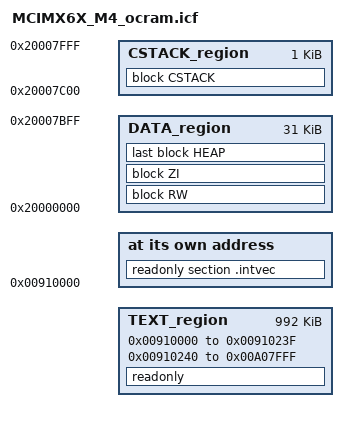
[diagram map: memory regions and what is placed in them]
/*
** ###################################################################
**     Processors:          MCIMX6Xxxxx08AB
**                          MCIMX6Xxxxx10AB
**
**     Compiler:            IAR ANSI C/C++ Compiler for ARM
**     Reference manual:    IMX6SXRM, Rev.A, February 2015
**     Version:             rev. 1.0, 2015-07-29
**
**     Abstract:
**         Linker file for the IAR ANSI C/C++ Compiler for ARM
**
**     Copyright (c) 2015 Freescale Semiconductor, Inc.
**     Copyright 2016 NXP
**     All rights reserved.
**
**     
**     SPDX-License-Identifier: BSD-3-Clause
**
**     http:                 www.freescale.com
**     mail:                 support@freescale.com
**
** ###################################################################
*/

define symbol m_interrupts_start       = 0x00910000;
define symbol m_interrupts_end         = 0x0091023F;

define symbol m_text_start             = 0x00910240;
define symbol m_text_end               = 0x00A07FFF;

define symbol m_data_start             = 0x20000000;
define symbol m_data_end               = 0x20007FFF;


/* Sizes */
if (isdefinedsymbol(__stack_size__)) {
  define symbol __size_cstack__        = __stack_size__;
} else {
  define symbol __size_cstack__        = 0x0400;
}

if (isdefinedsymbol(__heap_size__)) {
  define symbol __size_heap__          = __heap_size__;
} else {
  define symbol __size_heap__          = 0x0400;
}

define exported symbol __VECTOR_TABLE  = m_interrupts_start;
define exported symbol __FLASH_START   = m_interrupts_start;
define exported symbol __FLASH_END     = m_text_end;

define memory mem with size = 4G;
define region TEXT_region = mem:[from m_interrupts_start to m_interrupts_end]
                          | mem:[from m_text_start to m_text_end];
define region DATA_region = mem:[from m_data_start to m_data_end-__size_cstack__];
define region CSTACK_region = mem:[from m_data_end-__size_cstack__+1 to m_data_end];

define block CSTACK    with alignment = 8, size = __size_cstack__   { };
define block HEAP      with alignment = 8, size = __size_heap__     { };
define block RW        { readwrite };
define block ZI        { zi };

initialize by copy { readwrite, section .textrw };
do not initialize  { section .noinit };

place at address mem: m_interrupts_start    { readonly section .intvec };
place in TEXT_region                        { readonly };
place in DATA_region                        { block RW };
place in DATA_region                        { block ZI };
place in DATA_region                        { last block HEAP };
place in CSTACK_region                      { block CSTACK };
